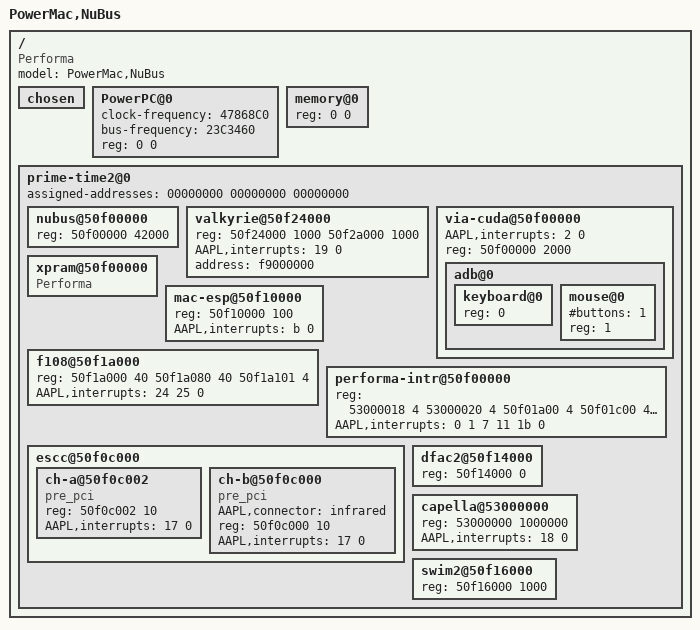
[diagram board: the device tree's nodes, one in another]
/*
 * NuBus Performa Device Tree Source
 */


/ {
	model = "PowerMac,NuBus";
	compatible = "Performa","MacRISC";
	#address-cells = <1>;
	#size-cells = <1>;

	chosen {
	};

	PowerPC@0 {
		device_type = "cpu";
		clock-frequency = <47868C0>;
		bus-frequency = <23C3460>;
		reg = <0 0>;
	};

	memory@0 {
		device_type = "memory";
		reg = <0 0>;
	};

	prime-time2@0 {
		device_type = "cpu-bus";
		#address-cells = <1>;
		#size-cells = <1>;
		/* a fake for early serial console */
		assigned-addresses = <00000000 00000000 00000000>;

	  	nubus@50f00000 {
			device_type = "nubus";
			reg = <50f00000 42000>;
			#address-cells = <1>;
			#size-cells = <1>;
		};

		valkyrie@50f24000 {
			device_type = "display";
			reg = <50f24000 1000 50f2a000 1000>;
			AAPL,interrupts = <19 0>;
			address = <f9000000>;
		};

		via-cuda@50f00000 {
			device_type = "cuda";
			AAPL,interrupts = <2 0>;
			reg = <50f00000 2000>;

			adb@0 {
				device_type = "adb";
				#address-cells = <1>;
				#size-cells = <0>;

				keyboard@0 {
					device_type = "keyboard";
					reg = <0>;
				};

				mouse@0 {
					device_type = "mouse";
					#buttons = <1>;
					reg = <1>;
				};
			};
		};

		xpram@50f00000 {
			device_type = "xpram";
			compatible = "Performa";
		};

		mac-esp@50f10000 {
			device_type = "scsi";
			reg = <50f10000 100>;
			AAPL,interrupts = <b 0>;
		};

		f108@50f1a000 {
			device_type = "ATA";
			reg = <50f1a000 40 50f1a080 40 50f1a101 4>;
			AAPL,interrupts = <24 25 0>;
		};

		performa-intr@50f00000 {
			device_type = "performa-intr";
			reg = <53000018 4 53000020 4 50f01a00 4 50f01c00 4 50f01800 4 50f00000 4 50f03a00 4 50f03c00 4 50f03e00 4 50f1a101 4>;
			AAPL,interrupts = <0 1 7 11 1b 0>;
		};

		escc@50f0c000 {
			device_type = "escc";
			#address-cells = <1>;
			#size-cells = <1>;

			ch-a@50f0c002 {
				device_type = "serial";
				compatible = "pre_pci";
				reg = <50f0c002 10>;
				AAPL,interrupts = <17 0>;
			};

			ch-b@50f0c000 {
				device_type = "serial";
				compatible = "pre_pci";
				AAPL,connector = "infrared";
				reg = <50f0c000 10>;
				AAPL,interrupts = <17 0>;
			};
		};

		dfac2@50f14000 {
			device_type = "sound";
			reg = <50f14000 0>;
		};

		capella@53000000 {
			device_type = "bridge";
			reg = <53000000 1000000>;
			AAPL,interrupts = <18 0>;
		};

		swim2@50f16000 {
			device_type = "block";
			reg = <50f16000 1000>;
		};
	};
};
